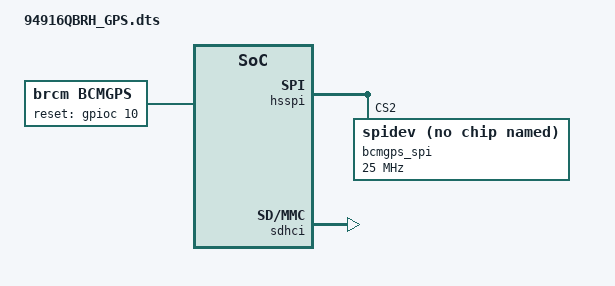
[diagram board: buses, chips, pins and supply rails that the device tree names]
#include "94916QBRH.dts"

/* *** SPI BUS *** */
/ {
	bcmgps: bcmgps {
		compatible = "brcm, bcmgps"; 
		ext_irq = <&bca_extintr 19 GPIO_ACTIVE_HIGH (BCA_EXTINTR_TYPE_HIGH_LEVEL | BCA_EXTINTR_TYPE_SENSE_EDGE)>;   /* host_req */
		reset-gpio = <&gpioc 10 GPIO_ACTIVE_HIGH>;  /* nStandby */
		spi-bus = <&bcmgps_spi>;
		status = "okay";
	};
};

&hsspi {
	status = "okay";
	bcmgps_spi: bcmgps_spi {
		pinctrl-names = "default"; 
		pinctrl-0 = <&hs_spim_ss_2_b_pin_52>;
		status = "okay";
		compatible = "rohm,dh2228fv";
		reg = <2>;
		spi-max-frequency = <25000000>;
	};
};

/* *** UART PORT *** */
/*
/ {
	bcmgps: bcmgps {
		compatible = "brcm, bcmgps"; 
		reset-gpio = <&gpioc 10 GPIO_ACTIVE_HIGH>;
		uart-port = <&hs_uart0>;
		status = "okay";
	};
};

&hs_uart0 {
	pinctrl-names = "default";
	pinctrl-0 = <&a_hs_uart_cts_n_pin_44 &a_hs_uart_rts_n_pin_43 &a_hs_uart_sdin_pin_51 &a_hs_uart_sdout_pin_42 >;
	status = "okay";
};
*/

&sdhci {
	brcm,sdhci-pll-baseclk-mhz = <5200>;
	status = "okay";
};
